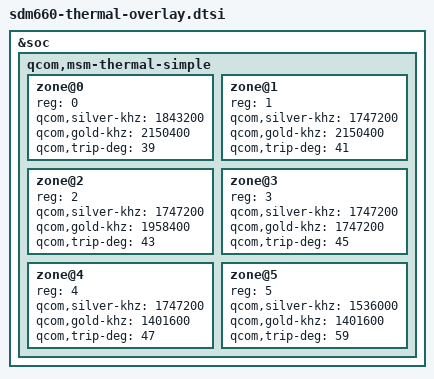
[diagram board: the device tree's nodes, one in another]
/* SPDX-License-Identifier: GPL-2.0 */

&soc {
	qcom,msm-thermal-simple {
	zone@0 {
			reg = <0>;
			qcom,silver-khz = <1843200>;
			qcom,gold-khz = <2150400>;
			qcom,trip-deg = <39>;
		};
	};
};

&soc {
	qcom,msm-thermal-simple {
	zone@1 {
			reg = <1>;
			qcom,silver-khz = <1747200>;
			qcom,gold-khz = <2150400>;
			qcom,trip-deg = <41>;
		};
	};
};

&soc {
	qcom,msm-thermal-simple {
		zone@2 {
			reg = <2>;
			qcom,silver-khz = <1747200>;
			qcom,gold-khz = <1958400>;
			qcom,trip-deg = <43>;
		};
	};
};

&soc {
	qcom,msm-thermal-simple {
		zone@3 {
			reg = <3>;
			qcom,silver-khz = <1747200>;
			qcom,gold-khz = <1747200>;
			qcom,trip-deg = <45>;
		};
	};
};

&soc {
	qcom,msm-thermal-simple {
		zone@4 {
			reg = <4>;
			qcom,silver-khz = <1747200>;
			qcom,gold-khz = <1401600>;
			qcom,trip-deg = <47>;
		};
	};
};

&soc {
	qcom,msm-thermal-simple {
		zone@5 {
			reg = <5>;
			qcom,silver-khz = <1536000>;
			qcom,gold-khz = <1401600>;
			qcom,trip-deg = <59>;
		};
	};
};
